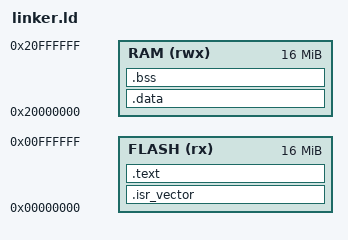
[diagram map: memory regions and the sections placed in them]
ENTRY(Reset_Handler)

MEMORY
{
    FLASH (rx)  : ORIGIN = 0x00000000, LENGTH = 16M
    RAM   (rwx) : ORIGIN = 0x20000000, LENGTH = 16M
}

/* Initial Stack Pointer */
_estack = ORIGIN(RAM) + LENGTH(RAM);

SECTIONS
{
    .isr_vector :
    {
        KEEP(*(.isr_vector))
    } > FLASH

    .text :
    {
        *(.text*)
        *(.rodata*)
    } > FLASH

    .data :
    {
        _sdata = .;
        *(.data*)
        _edata = .;
    } > RAM

    .bss :
    {
        _sbss = .;
        *(.bss*)
        *(COMMON)
        _ebss = .;
    } > RAM

    /DISCARD/ :
    {
        *(.comment)
        *(.note*)
    }
}
